AUTOSAR XML (schema 00046)
package /McInt/SwComponents
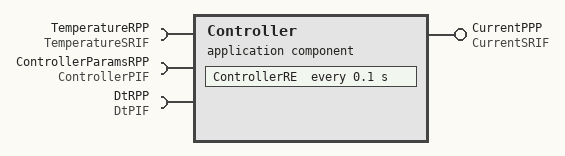
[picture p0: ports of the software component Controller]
  application sw component type Controller
    require port TemperatureRPP: required-interface=TemperatureSRIF  # Port to receive the temperature of the plant
    provide port CurrentPPP: provided-interface=CurrentSRIF  # Port for sending out the current output by this controller
    require port ControllerParamsRPP: required-interface=ControllerPIF  # Port to get the parameters for the controller
    require port DtRPP: required-interface=DtPIF  # Port to get delta t, i.e. time of one time step
    behavior ControllerInternalBehavior: data-type-mapping=DataTypeMappingSet, handle-termination-and-restart=NO-SUPPORT
      ar-typed-per-instance-memorys:
        data E: sw-addr-method=CODE, sw-calibration-access=READ-ONLY, type=Temperature_K  # Measurement point for the control error, the deviation between set point and acutal temperature of the plant, in the current time step
      timing event controller100ms: start-on-event=ControllerRE, period=0.1
      implicit-inter-runnable-variables:
        data ESum: sw-addr-method=CODE, sw-calibration-access=READ-ONLY, type=ESum, init-value=0 KelvinSecond  # Internal state of the controller: the sum of control errors
      runnable ControllerRE: sw-addr-method=CODE, symbol=controllerRE_func
        data-read-access:
          access DRA_temperature: accessed-variable=TemperatureRPP.T
        data-write-access:
          access DWA_current: accessed-variable=CurrentPPP.I
        4 x parameter access:
          PA_SetPoint: accessed-parameter=ControllerParamsRPP.ctrl_SetPoint
          PA_K: accessed-parameter=ControllerParamsRPP.ctrl_K
          PA_MaxESum: accessed-parameter=ControllerParamsRPP.ctrl_MaxESum
          PA_Dt: accessed-parameter=DtRPP.Dt
        read-local-variables:
          access ReadLocalVariables_ESum: accessed-variable=ESum
        written-local-variables:
          access WrittenLocalVariables_ESum: accessed-variable=ESum
